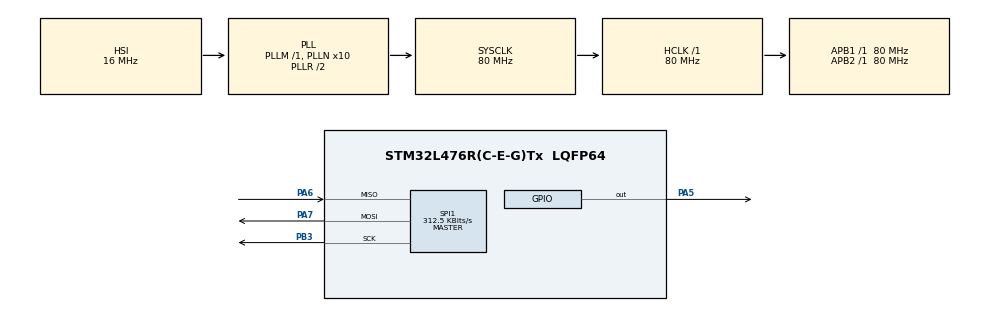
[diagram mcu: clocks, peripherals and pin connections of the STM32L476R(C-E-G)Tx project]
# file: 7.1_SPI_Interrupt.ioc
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Mcu.Family=STM32L4
Mcu.Name=STM32L476R(C-E-G)Tx
Mcu.Package=LQFP64
NVIC.PriorityGroup=NVIC_PRIORITYGROUP_4
NVIC.SPI1_IRQn=true\:0\:0\:false\:false\:true\:true\:true\:true
PA5.Signal=GPIO_Output
PA6.Mode=Full_Duplex_Master
PA6.Signal=SPI1_MISO
PA7.Mode=Full_Duplex_Master
PA7.Signal=SPI1_MOSI
PB3\ (JTDO-TRACESWO).Mode=Full_Duplex_Master
PB3\ (JTDO-TRACESWO).Signal=SPI1_SCK
ProjectManager.HeapSize=0x200
ProjectManager.StackSize=0x400
ProjectManager.TargetToolchain=STM32CubeIDE
RCC.ADCFreq_Value=64000000
RCC.AHBFreq_Value=80000000
RCC.APB1Freq_Value=80000000
RCC.APB1TimFreq_Value=80000000
RCC.APB2Freq_Value=80000000
RCC.APB2TimFreq_Value=80000000
RCC.CortexFreq_Value=80000000
RCC.HCLKFreq_Value=80000000
RCC.HSE_VALUE=8000000
RCC.HSI_VALUE=16000000
RCC.LSE_VALUE=32768
RCC.MSI_VALUE=4000000
RCC.PLLN=10
RCC.PLLSourceVirtual=RCC_PLLSOURCE_HSI
RCC.PREFETCH_ENABLE=1
RCC.SYSCLKFreq_VALUE=80000000
RCC.SYSCLKSource=RCC_SYSCLKSOURCE_PLLCLK
RCC.USBFreq_Value=64000000
RCC.VCOOutputFreq_Value=160000000
SPI1.BaudRatePrescaler=SPI_BAUDRATEPRESCALER_256
SPI1.CalculateBaudRate=312.5 KBits/s
SPI1.DataSize=SPI_DATASIZE_8BIT
SPI1.Direction=SPI_DIRECTION_2LINES
SPI1.Mode=SPI_MODE_MASTER
SPI1.VirtualType=VM_MASTER
board=NUCLEO-L476RG

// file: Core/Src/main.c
/* USER CODE BEGIN Header */
/**
 ******************************************************************************
 * @file           : main.c
 * @brief          : Main program body
 ******************************************************************************
 * @attention
 *
 * Copyright (c) 2024 STMicroelectronics.
 * All rights reserved.
 *
 * This software is licensed under terms that can be found in the LICENSE file
 * in the root directory of this software component.
 * If no LICENSE file comes with this software, it is provided AS-IS.
 *
 ******************************************************************************
 */
/* USER CODE END Header */
#include "main.h"

SPI_HandleTypeDef hspi1;

/* USER CODE BEGIN PV */
uint8_t buffer_tx[10] = { 71, 65, 50, 49, 25, 18, 111, 38, 121, 108 };
uint8_t buffer_rx[10];
uint8_t flag = 0;
/* USER CODE END PV */

void SystemClock_Config(void);
static void MX_GPIO_Init(void);
static void MX_SPI1_Init(void);

/* USER CODE BEGIN 0 */
void HAL_SPI_TxRxCpltCallback(SPI_HandleTypeDef *hspi)
{
	flag = 1;
	//HAL_GPIO_WritePin(GPIOA, GPIO_PIN_5, GPIO_PIN_SET);

}
/* USER CODE END 0 */

int main(void)
{

  /* MCU Configuration--------------------------------------------------------*/

  /* Reset of all peripherals, Initializes the Flash interface and the Systick. */
  HAL_Init();

  /* Configure the system clock */
  SystemClock_Config();

  /* Initialize all configured peripherals */
  MX_GPIO_Init();
  MX_SPI1_Init();
  /* USER CODE BEGIN 2 */
	//HAL_GPIO_WritePin(GPIOA, GPIO_PIN_5, GPIO_PIN_SET);
	HAL_SPI_TransmitReceive_IT(&hspi1, buffer_tx, buffer_rx, 10);
  /* USER CODE END 2 */

  /* Infinite loop */
	while (1) {

    /* USER CODE BEGIN 3 */
		if (flag == 1) {
			HAL_GPIO_WritePin(GPIOA, GPIO_PIN_5, GPIO_PIN_SET);
			HAL_Delay(5000);
			flag = 0;
		} else {
			HAL_GPIO_WritePin(GPIOA, GPIO_PIN_5, GPIO_PIN_RESET);
		}
	}
  /* USER CODE END 3 */
}

void SystemClock_Config(void)
{
  RCC_OscInitTypeDef RCC_OscInitStruct = {0};
  RCC_ClkInitTypeDef RCC_ClkInitStruct = {0};

  /** Configure the main internal regulator output voltage
  */
  if (HAL_PWREx_ControlVoltageScaling(PWR_REGULATOR_VOLTAGE_SCALE1) != HAL_OK)
  {
    Error_Handler();
  }

  /** Initializes the RCC Oscillators according to the specified parameters
  * in the RCC_OscInitTypeDef structure.
  */
  RCC_OscInitStruct.OscillatorType = RCC_OSCILLATORTYPE_HSI;
  RCC_OscInitStruct.HSIState = RCC_HSI_ON;
  RCC_OscInitStruct.HSICalibrationValue = RCC_HSICALIBRATION_DEFAULT;
  RCC_OscInitStruct.PLL.PLLState = RCC_PLL_ON;
  RCC_OscInitStruct.PLL.PLLSource = RCC_PLLSOURCE_HSI;
  RCC_OscInitStruct.PLL.PLLM = 1;
  RCC_OscInitStruct.PLL.PLLN = 10;
  RCC_OscInitStruct.PLL.PLLP = RCC_PLLP_DIV7;
  RCC_OscInitStruct.PLL.PLLQ = RCC_PLLQ_DIV2;
  RCC_OscInitStruct.PLL.PLLR = RCC_PLLR_DIV2;
  if (HAL_RCC_OscConfig(&RCC_OscInitStruct) != HAL_OK)
  {
    Error_Handler();
  }

  /** Initializes the CPU, AHB and APB buses clocks
  */
  RCC_ClkInitStruct.ClockType = RCC_CLOCKTYPE_HCLK|RCC_CLOCKTYPE_SYSCLK
                              |RCC_CLOCKTYPE_PCLK1|RCC_CLOCKTYPE_PCLK2;
  RCC_ClkInitStruct.SYSCLKSource = RCC_SYSCLKSOURCE_PLLCLK;
  RCC_ClkInitStruct.AHBCLKDivider = RCC_SYSCLK_DIV1;
  RCC_ClkInitStruct.APB1CLKDivider = RCC_HCLK_DIV1;
  RCC_ClkInitStruct.APB2CLKDivider = RCC_HCLK_DIV1;

  if (HAL_RCC_ClockConfig(&RCC_ClkInitStruct, FLASH_LATENCY_4) != HAL_OK)
  {
    Error_Handler();
  }
}

static void MX_SPI1_Init(void)
{

  /* SPI1 parameter configuration*/
  hspi1.Instance = SPI1;
  hspi1.Init.Mode = SPI_MODE_MASTER;
  hspi1.Init.Direction = SPI_DIRECTION_2LINES;
  hspi1.Init.DataSize = SPI_DATASIZE_8BIT;
  hspi1.Init.CLKPolarity = SPI_POLARITY_LOW;
  hspi1.Init.CLKPhase = SPI_PHASE_1EDGE;
  hspi1.Init.NSS = SPI_NSS_SOFT;
  hspi1.Init.BaudRatePrescaler = SPI_BAUDRATEPRESCALER_256;
  hspi1.Init.FirstBit = SPI_FIRSTBIT_MSB;
  hspi1.Init.TIMode = SPI_TIMODE_DISABLE;
  hspi1.Init.CRCCalculation = SPI_CRCCALCULATION_DISABLE;
  hspi1.Init.CRCPolynomial = 7;
  hspi1.Init.CRCLength = SPI_CRC_LENGTH_DATASIZE;
  hspi1.Init.NSSPMode = SPI_NSS_PULSE_ENABLE;
  if (HAL_SPI_Init(&hspi1) != HAL_OK)
  {
    Error_Handler();
  }

}

static void MX_GPIO_Init(void)
{
  GPIO_InitTypeDef GPIO_InitStruct = {0};

  /* GPIO Ports Clock Enable */
  __HAL_RCC_GPIOA_CLK_ENABLE();
  __HAL_RCC_GPIOB_CLK_ENABLE();

  /*Configure GPIO pin Output Level */
  HAL_GPIO_WritePin(GPIOA, GPIO_PIN_5, GPIO_PIN_RESET);

  /*Configure GPIO pin : PA5 */
  GPIO_InitStruct.Pin = GPIO_PIN_5;
  GPIO_InitStruct.Mode = GPIO_MODE_OUTPUT_PP;
  GPIO_InitStruct.Pull = GPIO_NOPULL;
  GPIO_InitStruct.Speed = GPIO_SPEED_FREQ_LOW;
  HAL_GPIO_Init(GPIOA, &GPIO_InitStruct);

}

void Error_Handler(void)
{
	__disable_irq();
	while (1) {
	}
}
